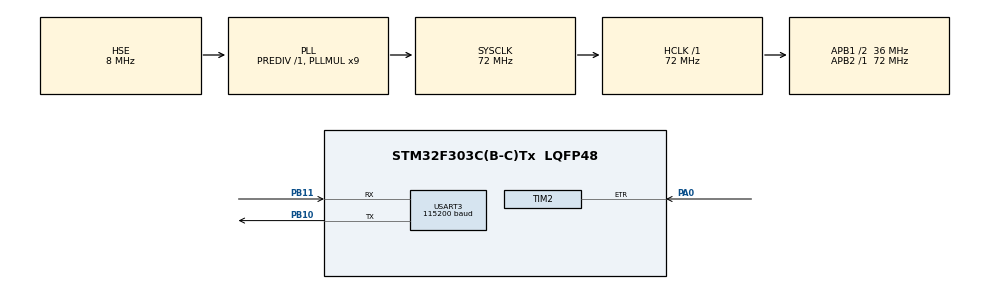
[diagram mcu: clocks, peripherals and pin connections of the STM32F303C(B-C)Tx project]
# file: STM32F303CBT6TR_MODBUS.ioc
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Mcu.Family=STM32F3
Mcu.Name=STM32F303C(B-C)Tx
Mcu.Package=LQFP48
NVIC.PriorityGroup=NVIC_PRIORITYGROUP_4
NVIC.TIM3_IRQn=true\:0\:0\:false\:false\:true\:true\:true\:true
NVIC.TIM6_DAC_IRQn=true\:0\:0\:false\:false\:true\:true\:true\:true
NVIC.TIM7_IRQn=true\:0\:0\:false\:false\:true\:true\:true\:true
NVIC.USART3_IRQn=true\:0\:0\:false\:false\:true\:true\:true\:true
PA0.Signal=S_TIM2_CH1_ETR
PB10.Mode=Asynchronous
PB10.Signal=USART3_TX
PB11.Mode=Asynchronous
PB11.Signal=USART3_RX
PF0-OSC_IN.Mode=HSE-External-Oscillator
PF0-OSC_IN.Signal=RCC_OSC_IN
PF1-OSC_OUT.Mode=HSE-External-Oscillator
PF1-OSC_OUT.Signal=RCC_OSC_OUT
ProjectManager.HeapSize=0x200
ProjectManager.StackSize=0x400
ProjectManager.TargetToolchain=STM32CubeIDE
RCC.AHBFreq_Value=72000000
RCC.APB1CLKDivider=RCC_HCLK_DIV2
RCC.APB1Freq_Value=36000000
RCC.APB1TimFreq_Value=72000000
RCC.APB2Freq_Value=72000000
RCC.APB2TimFreq_Value=72000000
RCC.CortexFreq_Value=72000000
RCC.HCLKFreq_Value=72000000
RCC.HSE_VALUE=8000000
RCC.HSI_VALUE=8000000
RCC.LSE_VALUE=32768
RCC.PLLMUL=RCC_PLL_MUL9
RCC.PLLSourceVirtual=RCC_PLLSOURCE_HSE
RCC.SYSCLKFreq_VALUE=72000000
RCC.SYSCLKSourceVirtual=RCC_SYSCLKSOURCE_PLLCLK
RCC.USBFreq_Value=72000000
SH.S_TIM2_CH1_ETR.0=TIM2_ETR,ClockSourceETR_Mode2
TIM3.AutoReloadPreload=TIM_AUTORELOAD_PRELOAD_ENABLE
TIM3.Period=9999
TIM3.Prescaler=719
TIM6.Period=750
TIM6.Prescaler=71
TIM6.TIM_MasterOutputTrigger=TIM_TRGO_ENABLE
TIM7.AutoReloadPreload=TIM_AUTORELOAD_PRELOAD_ENABLE
TIM7.Period=1750
TIM7.Prescaler=71
TIM7.TIM_MasterOutputTrigger=TIM_TRGO_ENABLE
USART3.BaudRate=115200
USART3.VirtualMode-Asynchronous=VM_ASYNC
VP_TIM3_VS_ClockSourceINT.Mode=Internal
VP_TIM6_VS_ClockSourceINT.Mode=Enable_Timer
VP_TIM7_VS_ClockSourceINT.Mode=Enable_Timer
board=custom

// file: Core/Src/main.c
/* USER CODE BEGIN Header */
/**
  ******************************************************************************
  * @file           : main.c
  * @brief          : Main program body
  ******************************************************************************
  * @attention
  *
  * Copyright (c) 2023 STMicroelectronics.
  * All rights reserved.
  *
  * This software is licensed under terms that can be found in the LICENSE file
  * in the root directory of this software component.
  * If no LICENSE file comes with this software, it is provided AS-IS.
  *
  ******************************************************************************
  */
/* USER CODE END Header */
#include "main.h"

TIM_HandleTypeDef htim2;
TIM_HandleTypeDef htim3;
TIM_HandleTypeDef htim6;
TIM_HandleTypeDef htim7;

UART_HandleTypeDef huart3;

/* USER CODE BEGIN PV */
unsigned int Counts; // 100ms pulse counter count data
/* USER CODE END PV */

void SystemClock_Config(void);
static void MX_GPIO_Init(void);
static void MX_USART3_UART_Init(void);
static void MX_TIM6_Init(void);
static void MX_TIM7_Init(void);
static void MX_TIM2_Init(void);
static void MX_TIM3_Init(void);

/* USER CODE BEGIN 0 */
void HAL_TIM_PeriodElapsedCallback(TIM_HandleTypeDef *htim) {

	/* This function is called when the respective timer overflows
	 * it is used for 100ms timer, i.e. TIM3
	 * When the 100 ms passed the count value on the TIM2, i.e. pulse counter, saved in to the first Holding Register
	 * See below for further details.
	 * */

	/********************** Pulse Counter **********************/
	if (htim->Instance == TIM3) {

		Counts = TIM2->CNT;

		if (Counts <= 65535) { //the biggest number that can be sent with single 16-bit holding register

			// note that first element of holding register is for counts
			Update_Holding_Register_value(Counts, 0);

		} else {
			// to prevent overflow, i.e. the highest possible count can't be exceeded
			Update_Holding_Register_value(65535, 0);
		}

		TIM3->CNT = 0; //Reset the timers
		TIM2->CNT = 0;
	}
}

/* USER CODE END 0 */

int main(void)
{

  /* MCU Configuration--------------------------------------------------------*/

  /* Reset of all peripherals, Initializes the Flash interface and the Systick. */
  HAL_Init();

  /* Configure the system clock */
  SystemClock_Config();

  /* Initialize all configured peripherals */
  MX_GPIO_Init();
  MX_USART3_UART_Init();
  MX_TIM6_Init();
  MX_TIM7_Init();
  MX_TIM2_Init();
  MX_TIM3_Init();

  /* Infinite loop */
  /* USER CODE BEGIN WHILE */

  MB_Init(); //For Modbus implementation

	/*-------------------------- PULSE COUNTER FEATURE FOR RECEIVING COUNTS --------------------------*/

	/* TODO add pulse counter description to readme.md and make this a driver!
	 * Note there are additional comments on the HAL_TIM_PeriodElapsedCallback function
	 * Also one should define Counts variable (it is defined above)*/

	/*Start the 100ms timer (the psc of tim3 is 719 (720-1) and the overflow is 9,999(10,000-1).
	 *  Therefore in every 100ms it overflows and generates an interrupt)
	 *  (internal 72MHz clock should be selected)
	 *  The interrupt function HAL_TIM_PeriodElapsedCallback can be found in the main.c
	 *  To use one should enable the auto reload and TIM3 global interrupt (in the NVIC) features*/
	HAL_TIM_Base_Start_IT(&htim3);

	/*Start the pulse counter. it is TIM2.
	 * Receives the counter clock externally(PA0)
	 * To use one should select the clock source of the TIM2 as ETR2*/
	HAL_TIM_Base_Start(&htim2);
	/* There are also some more code lines on the HAL_TIM_PeriodElapsedCallback function above */

	/*--------------------------------------------------------------------------------------------------*/

	while (1)
	{

    /* USER CODE END WHILE */

  }
}

void SystemClock_Config(void)
{
  RCC_OscInitTypeDef RCC_OscInitStruct = {0};
  RCC_ClkInitTypeDef RCC_ClkInitStruct = {0};
  RCC_PeriphCLKInitTypeDef PeriphClkInit = {0};

  /** Initializes the RCC Oscillators according to the specified parameters
  * in the RCC_OscInitTypeDef structure.
  */
  RCC_OscInitStruct.OscillatorType = RCC_OSCILLATORTYPE_HSE;
  RCC_OscInitStruct.HSEState = RCC_HSE_ON;
  RCC_OscInitStruct.HSEPredivValue = RCC_HSE_PREDIV_DIV1;
  RCC_OscInitStruct.HSIState = RCC_HSI_ON;
  RCC_OscInitStruct.PLL.PLLState = RCC_PLL_ON;
  RCC_OscInitStruct.PLL.PLLSource = RCC_PLLSOURCE_HSE;
  RCC_OscInitStruct.PLL.PLLMUL = RCC_PLL_MUL9;
  if (HAL_RCC_OscConfig(&RCC_OscInitStruct) != HAL_OK)
  {
    Error_Handler();
  }

  /** Initializes the CPU, AHB and APB buses clocks
  */
  RCC_ClkInitStruct.ClockType = RCC_CLOCKTYPE_HCLK|RCC_CLOCKTYPE_SYSCLK
                              |RCC_CLOCKTYPE_PCLK1|RCC_CLOCKTYPE_PCLK2;
  RCC_ClkInitStruct.SYSCLKSource = RCC_SYSCLKSOURCE_PLLCLK;
  RCC_ClkInitStruct.AHBCLKDivider = RCC_SYSCLK_DIV1;
  RCC_ClkInitStruct.APB1CLKDivider = RCC_HCLK_DIV2;
  RCC_ClkInitStruct.APB2CLKDivider = RCC_HCLK_DIV1;

  if (HAL_RCC_ClockConfig(&RCC_ClkInitStruct, FLASH_LATENCY_2) != HAL_OK)
  {
    Error_Handler();
  }
  PeriphClkInit.PeriphClockSelection = RCC_PERIPHCLK_USART3;
  PeriphClkInit.Usart3ClockSelection = RCC_USART3CLKSOURCE_PCLK1;
  if (HAL_RCCEx_PeriphCLKConfig(&PeriphClkInit) != HAL_OK)
  {
    Error_Handler();
  }
}

static void MX_TIM2_Init(void)
{

  TIM_ClockConfigTypeDef sClockSourceConfig = {0};
  TIM_MasterConfigTypeDef sMasterConfig = {0};

  htim2.Instance = TIM2;
  htim2.Init.Prescaler = 0;
  htim2.Init.CounterMode = TIM_COUNTERMODE_UP;
  htim2.Init.Period = 4294967295;
  htim2.Init.ClockDivision = TIM_CLOCKDIVISION_DIV1;
  htim2.Init.AutoReloadPreload = TIM_AUTORELOAD_PRELOAD_DISABLE;
  if (HAL_TIM_Base_Init(&htim2) != HAL_OK)
  {
    Error_Handler();
  }
  sClockSourceConfig.ClockSource = TIM_CLOCKSOURCE_ETRMODE2;
  sClockSourceConfig.ClockPolarity = TIM_CLOCKPOLARITY_NONINVERTED;
  sClockSourceConfig.ClockPrescaler = TIM_CLOCKPRESCALER_DIV1;
  sClockSourceConfig.ClockFilter = 0;
  if (HAL_TIM_ConfigClockSource(&htim2, &sClockSourceConfig) != HAL_OK)
  {
    Error_Handler();
  }
  sMasterConfig.MasterOutputTrigger = TIM_TRGO_RESET;
  sMasterConfig.MasterSlaveMode = TIM_MASTERSLAVEMODE_DISABLE;
  if (HAL_TIMEx_MasterConfigSynchronization(&htim2, &sMasterConfig) != HAL_OK)
  {
    Error_Handler();
  }

}

static void MX_TIM3_Init(void)
{

  TIM_ClockConfigTypeDef sClockSourceConfig = {0};
  TIM_MasterConfigTypeDef sMasterConfig = {0};

  htim3.Instance = TIM3;
  htim3.Init.Prescaler = 719;
  htim3.Init.CounterMode = TIM_COUNTERMODE_UP;
  htim3.Init.Period = 9999;
  htim3.Init.ClockDivision = TIM_CLOCKDIVISION_DIV1;
  htim3.Init.AutoReloadPreload = TIM_AUTORELOAD_PRELOAD_ENABLE;
  if (HAL_TIM_Base_Init(&htim3) != HAL_OK)
  {
    Error_Handler();
  }
  sClockSourceConfig.ClockSource = TIM_CLOCKSOURCE_INTERNAL;
  if (HAL_TIM_ConfigClockSource(&htim3, &sClockSourceConfig) != HAL_OK)
  {
    Error_Handler();
  }
  sMasterConfig.MasterOutputTrigger = TIM_TRGO_RESET;
  sMasterConfig.MasterSlaveMode = TIM_MASTERSLAVEMODE_DISABLE;
  if (HAL_TIMEx_MasterConfigSynchronization(&htim3, &sMasterConfig) != HAL_OK)
  {
    Error_Handler();
  }

}

static void MX_TIM6_Init(void)
{

  TIM_MasterConfigTypeDef sMasterConfig = {0};

  htim6.Instance = TIM6;
  htim6.Init.Prescaler = 71;
  htim6.Init.CounterMode = TIM_COUNTERMODE_UP;
  htim6.Init.Period = 750;
  htim6.Init.AutoReloadPreload = TIM_AUTORELOAD_PRELOAD_DISABLE;
  if (HAL_TIM_Base_Init(&htim6) != HAL_OK)
  {
    Error_Handler();
  }
  sMasterConfig.MasterOutputTrigger = TIM_TRGO_ENABLE;
  sMasterConfig.MasterSlaveMode = TIM_MASTERSLAVEMODE_DISABLE;
  if (HAL_TIMEx_MasterConfigSynchronization(&htim6, &sMasterConfig) != HAL_OK)
  {
    Error_Handler();
  }

}

static void MX_TIM7_Init(void)
{

  TIM_MasterConfigTypeDef sMasterConfig = {0};

  htim7.Instance = TIM7;
  htim7.Init.Prescaler = 71;
  htim7.Init.CounterMode = TIM_COUNTERMODE_UP;
  htim7.Init.Period = 1750;
  htim7.Init.AutoReloadPreload = TIM_AUTORELOAD_PRELOAD_ENABLE;
  if (HAL_TIM_Base_Init(&htim7) != HAL_OK)
  {
    Error_Handler();
  }
  sMasterConfig.MasterOutputTrigger = TIM_TRGO_ENABLE;
  sMasterConfig.MasterSlaveMode = TIM_MASTERSLAVEMODE_DISABLE;
  if (HAL_TIMEx_MasterConfigSynchronization(&htim7, &sMasterConfig) != HAL_OK)
  {
    Error_Handler();
  }

}

static void MX_USART3_UART_Init(void)
{

  huart3.Instance = USART3;
  huart3.Init.BaudRate = 115200;
  huart3.Init.WordLength = UART_WORDLENGTH_8B;
  huart3.Init.StopBits = UART_STOPBITS_1;
  huart3.Init.Parity = UART_PARITY_NONE;
  huart3.Init.Mode = UART_MODE_TX_RX;
  huart3.Init.HwFlowCtl = UART_HWCONTROL_NONE;
  huart3.Init.OverSampling = UART_OVERSAMPLING_16;
  huart3.Init.OneBitSampling = UART_ONE_BIT_SAMPLE_DISABLE;
  huart3.AdvancedInit.AdvFeatureInit = UART_ADVFEATURE_NO_INIT;
  if (HAL_UART_Init(&huart3) != HAL_OK)
  {
    Error_Handler();
  }

}

static void MX_GPIO_Init(void)
{

  /* GPIO Ports Clock Enable */
  __HAL_RCC_GPIOF_CLK_ENABLE();
  __HAL_RCC_GPIOA_CLK_ENABLE();
  __HAL_RCC_GPIOB_CLK_ENABLE();

}

void Error_Handler(void)
{
  __disable_irq();
  while (1)
  {
  }
}
